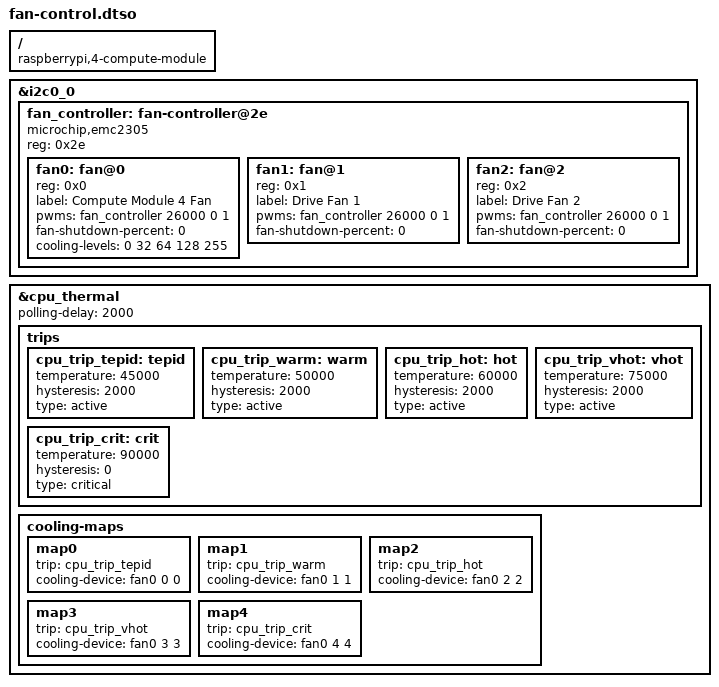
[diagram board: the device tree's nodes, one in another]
/*
 * DT overlay for adding external PWM fan control to the Exaviz Interceptor
 * carrier board v1.0 for the Raspberry Pi Compute Module 4.
 *
 * This expects a Microchip EMC2305 fan controller connected to I²C on the J9
 * FFC connector (pins 10, 11, 12, 13 are 3.3V, ID_SD, ID_SC, GND), with an
 * external 4.7kΩ pull up to 3.3V on ADDR_SEL for the 0x2e address.
 */

/dts-v1/;
/plugin/;

/ {
	compatible = "raspberrypi,4-compute-module";
};

&i2c0_0 {
	fan_controller: fan-controller@2e {
		compatible = "microchip,emc2305";
		reg = <0x2e>;
		#address-cells = <1>;
		#size-cells = <0>;
		#pwm-cells = <3>;

		fan0: fan@0 {
			reg = <0x0>;
			label = "Compute Module 4 Fan";
			pwms = <&fan_controller 26000 0 1>;
			fan-shutdown-percent = <0>;
			cooling-levels = <0 32 64 128 255>;
			#cooling-cells = <2>;
		};

		fan1: fan@1 {
			reg = <0x1>;
			label = "Drive Fan 1";
			pwms = <&fan_controller 26000 0 1>;
			fan-shutdown-percent = <0>;
		};

		fan2: fan@2 {
			reg = <0x2>;
			label = "Drive Fan 2";
			pwms = <&fan_controller 26000 0 1>;
			fan-shutdown-percent = <0>;
		};
	};
};

&cpu_thermal {
	polling-delay = <2000>;

	trips {
		cpu_trip_tepid: tepid {
			temperature = <45000>;
			hysteresis = <2000>;
			type = "active";
		};

		cpu_trip_warm: warm {
			temperature = <50000>;
			hysteresis = <2000>;
			type = "active";
		};

		cpu_trip_hot: hot {
			temperature = <60000>;
			hysteresis = <2000>;
			type = "active";
		};

		cpu_trip_vhot: vhot {
			temperature = <75000>;
			hysteresis = <2000>;
			type = "active";
		};

		cpu_trip_crit: crit {
			temperature = <90000>;
			hysteresis = <0>;
			type = "critical";
		};
	};

	cooling-maps {
		map0 {
			trip = <&cpu_trip_tepid>;
			cooling-device = <&fan0 0 0>;
		};

		map1 {
			trip = <&cpu_trip_warm>;
			cooling-device = <&fan0 1 1>;
		};

		map2 {
			trip = <&cpu_trip_hot>;
			cooling-device = <&fan0 2 2>;
		};

		map3 {
			trip = <&cpu_trip_vhot>;
			cooling-device = <&fan0 3 3>;
		};

		map4 {
			trip = <&cpu_trip_crit>;
			cooling-device = <&fan0 4 4>;
		};
	};
};
